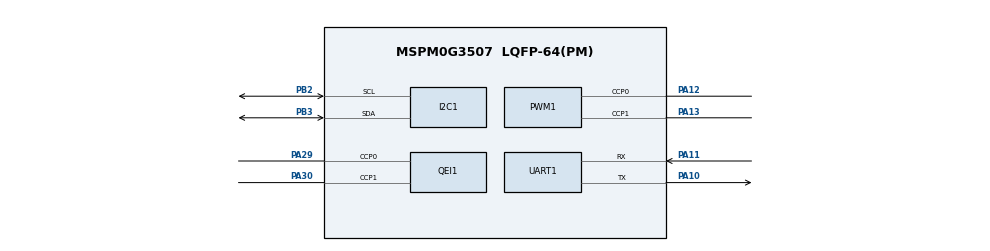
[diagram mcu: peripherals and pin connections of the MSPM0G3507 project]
/**
 * These arguments were used when this file was generated. They will be automatically applied on subsequent loads
 * via the GUI or CLI. Run CLI with '--help' for additional information on how to override these arguments.
 */
//@cliArgs --device "MSPM0G350X" --package "LQFP-64(PM)" --part "Default"
//@v2CliArgs --device "MSPM0G3507" --package "LQFP-64(PM)"
// @cliArgs --board /ti/boards/LP_MSPM0G3507 --rtos nortos

/**
 * Import the modules used in this configuration.
 */
const GPIO   = scripting.addModule("/ti/driverlib/GPIO", {}, false);
const GPIO1  = GPIO.addInstance();
const GPIO2  = GPIO.addInstance();
const I2C    = scripting.addModule("/ti/driverlib/I2C", {}, false);
const I2C1   = I2C.addInstance();
const PWM    = scripting.addModule("/ti/driverlib/PWM", {}, false);
const PWM1   = PWM.addInstance();
const QEI    = scripting.addModule("/ti/driverlib/QEI", {}, false);
const QEI1   = QEI.addInstance();
const SYSCTL = scripting.addModule("/ti/driverlib/SYSCTL");
const TIMER  = scripting.addModule("/ti/driverlib/TIMER", {}, false);
const TIMER1 = TIMER.addInstance();
const UART   = scripting.addModule("/ti/driverlib/UART", {}, false);
const UART1  = UART.addInstance();

/**
 * Write custom configuration values to the imported modules.
 */
GPIO1.$name = "GPIO_TB6612_CTRL";
GPIO1.associatedPins.create(5);
GPIO1.associatedPins[0].$name        = "M1_AIN1";
GPIO1.associatedPins[0].assignedPort = "PORTB";
GPIO1.associatedPins[0].assignedPin  = "0";
GPIO1.associatedPins[0].initialValue = "SET";
GPIO1.associatedPins[1].$name        = "M1_AIN2";
GPIO1.associatedPins[1].assignedPort = "PORTB";
GPIO1.associatedPins[1].assignedPin  = "1";
GPIO1.associatedPins[2].$name        = "M2_BIN1";
GPIO1.associatedPins[2].assignedPort = "PORTB";
GPIO1.associatedPins[2].assignedPin  = "8";
GPIO1.associatedPins[3].$name        = "M2_BIN2";
GPIO1.associatedPins[3].assignedPort = "PORTB";
GPIO1.associatedPins[3].assignedPin  = "9";
GPIO1.associatedPins[4].$name        = "DRV_STBY";
GPIO1.associatedPins[4].assignedPort = "PORTB";
GPIO1.associatedPins[4].assignedPin  = "16";
GPIO1.associatedPins[4].initialValue = "SET";

GPIO2.$name = "GPIO_ENC2_INPUT";
GPIO2.associatedPins.create(2);
GPIO2.associatedPins[0].$name            = "ENC2_A";
GPIO2.associatedPins[0].direction        = "INPUT";
GPIO2.associatedPins[0].assignedPort     = "PORTB";
GPIO2.associatedPins[0].assignedPin      = "6";
GPIO2.associatedPins[0].internalResistor = "PULL_UP";
GPIO2.associatedPins[1].$name            = "ENC2_B";
GPIO2.associatedPins[1].direction        = "INPUT";
GPIO2.associatedPins[1].assignedPort     = "PORTB";
GPIO2.associatedPins[1].assignedPin      = "7";
GPIO2.associatedPins[1].internalResistor = "PULL_UP";

I2C1.$name                     = "I2C_MPU6050";
I2C1.basicEnableController     = true;
I2C1.basicControllerBusSpeed   = 400000;
I2C1.peripheral.sclPin.$assign = "PB2";
I2C1.peripheral.sdaPin.$assign = "PB3";

PWM1.$name                      = "PWM_TB6612";
PWM1.clockPrescale              = 1;
PWM1.timerCount                 = 2000;
PWM1.peripheral.$assign         = "TIMG0";
PWM1.peripheral.ccp0Pin.$assign = "PA12"; /* PWMA */
PWM1.peripheral.ccp1Pin.$assign = "PA13"; /* PWMB */
PWM1.PWM_CHANNEL_0.$name        = "M1_PWM";
PWM1.PWM_CHANNEL_1.$name        = "M2_PWM";

QEI1.$name                      = "QEI_ENC1";
QEI1.peripheral.$assign         = "TIMG8";
QEI1.peripheral.ccp0Pin.$assign = "PA29";
QEI1.peripheral.ccp1Pin.$assign = "PA30";

TIMER1.$name              = "TIMER_CTRL_TICK";
TIMER1.profile            = "Basic_Periodic";
TIMER1.peripheral.$assign = "TIMG6";

UART1.$name                    = "UART_OPENMV";
UART1.enableFIFO               = true;
UART1.enableDMARX              = false;
UART1.enableDMATX              = false;
UART1.targetBaudRate           = 115200;
UART1.peripheral.$assign       = "UART0";
UART1.peripheral.txPin.$assign = "PA10";
UART1.peripheral.rxPin.$assign = "PA11";

const Board = scripting.addModule("/ti/driverlib/Board", {}, false);

SYSCTL.forceDefaultClkConfig = true;
SYSCTL.clockTreeEn           = true;
